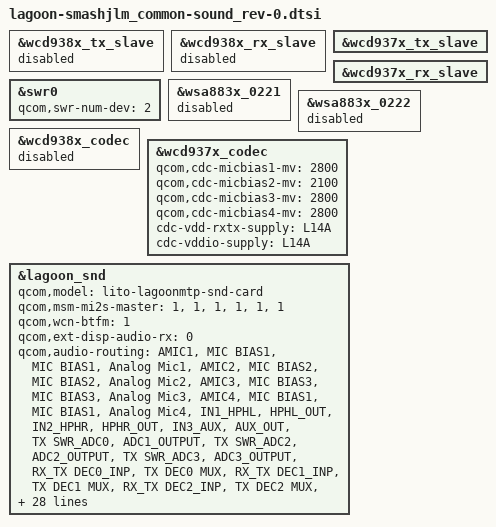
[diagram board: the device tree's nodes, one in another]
// SPDX-License-Identifier: GPL-2.0-only
/*
 * Copyright (c) 2018-2019, The Linux Foundation. All rights reserved.
 */

&wcd938x_tx_slave {
	status = "disabled";
};
&wcd938x_rx_slave {
	status = "disabled";
};
&wcd937x_tx_slave {
	status = "okay";
};
&wcd937x_rx_slave {
	status = "okay";
};
&swr0 {
	qcom,swr-num-dev = <2>;
};
&wsa883x_0221 {
	status = "disabled";
};
&wsa883x_0222 {
	status = "disabled";
};

&wcd938x_codec {
        status = "disabled";
};

&wcd937x_codec {
	qcom,cdc-micbias1-mv = <2800>;
	qcom,cdc-micbias2-mv = <2100>;
	qcom,cdc-micbias3-mv = <2800>;
	qcom,cdc-micbias4-mv = <2800>;

	cdc-vdd-rxtx-supply = <&L14A>;
	cdc-vddio-supply = <&L14A>;

	status = "okay";
};

&lagoon_snd {
	qcom,model = "lito-lagoonmtp-snd-card";
	qcom,msm-mi2s-master = <1>, <1>, <1>, <1>, <1>, <1>;
	qcom,wcn-btfm = <1>;
	qcom,ext-disp-audio-rx = <0>;
	qcom,audio-routing =
		"AMIC1", "MIC BIAS1",
		"MIC BIAS1", "Analog Mic1",
		"AMIC2", "MIC BIAS2",
		"MIC BIAS2", "Analog Mic2",
		"AMIC3", "MIC BIAS3",
		"MIC BIAS3", "Analog Mic3",
		"AMIC4", "MIC BIAS1",
		"MIC BIAS1", "Analog Mic4",
		"IN1_HPHL", "HPHL_OUT",
		"IN2_HPHR", "HPHR_OUT",
		"IN3_AUX", "AUX_OUT",
		"TX SWR_ADC0", "ADC1_OUTPUT",
		"TX SWR_ADC2", "ADC2_OUTPUT",
		"TX SWR_ADC3", "ADC3_OUTPUT",
		"RX_TX DEC0_INP", "TX DEC0 MUX",
		"RX_TX DEC1_INP", "TX DEC1 MUX",
		"RX_TX DEC2_INP", "TX DEC2 MUX",
		"RX_TX DEC3_INP", "TX DEC3 MUX",
		"VA_AIF1 CAP", "VA_SWR_CLK",
		"VA_AIF2 CAP", "VA_SWR_CLK",
		"VA_AIF3 CAP", "VA_SWR_CLK",
		"VA SWR_ADC0", "VA_SWR_CLK",
		"VA SWR_ADC1", "VA_SWR_CLK",
		"VA SWR_ADC2", "VA_SWR_CLK",
		"VA SWR_ADC3", "VA_SWR_CLK",
		"VA SWR_MIC0", "VA_SWR_CLK",
		"VA SWR_MIC1", "VA_SWR_CLK",
		"VA SWR_MIC2", "VA_SWR_CLK",
		"VA SWR_MIC3", "VA_SWR_CLK",
		"VA SWR_MIC4", "VA_SWR_CLK",
		"VA SWR_MIC5", "VA_SWR_CLK",
		"VA SWR_MIC6", "VA_SWR_CLK",
		"VA SWR_MIC7", "VA_SWR_CLK",
		"VA SWR_ADC0", "ADC1_OUTPUT",
		"VA SWR_ADC2", "ADC2_OUTPUT",
		"VA SWR_ADC3", "ADC3_OUTPUT";

	qcom,msm-mbhc-hphl-swh = <1>;
	qcom,msm-mbhc-gnd-swh = <0>;
	lge,fmradio-lna-enable-gpio = <&tlmm 74 0x00>;
	lna-supply = <&pm6350_l11>;
	asoc-codec  = <&stub_codec>, <&bolero>, <&tfa98xx_spk1>, <&tfa98xx_spk2>;
	asoc-codec-names = "msm-stub-codec.1", "bolero_codec", "tfa98xx-codec.0034", "tfa98xx-codec.0035";
	qcom,wsa-max-devs = <0>;
	qcom,codec-max-aux-devs = <1>;
	qcom,msm-mbhc-usbc-audio-supported = <0>;
	qcom,codec-aux-devs = <&wcd937x_codec>;
	qcom,msm_audio_ssr_devs = <&audio_apr>, <&q6core>,
				  <&lpi_tlmm>, <&bolero>;
};

